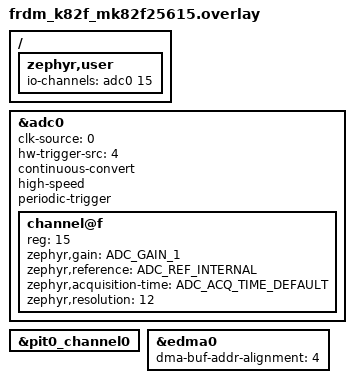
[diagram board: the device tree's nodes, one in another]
/*
 * SPDX-License-Identifier: Apache-2.0
 *
 * Copyright (c) 2023 Benjamin Björnsson <benjamin.bjornsson@gmail.com>
 */

/ {
	zephyr,user {
		io-channels = <&adc0 15>;
	};
};

&adc0 {
	#address-cells = <1>;
	#size-cells = <0>;
	clk-source = <0>;
	hw-trigger-src = <4>;
	continuous-convert;
	high-speed;
	periodic-trigger;
	status = "okay";

	channel@f {
		reg = <15>;
		zephyr,gain = "ADC_GAIN_1";
		zephyr,reference = "ADC_REF_INTERNAL";
		zephyr,acquisition-time = <ADC_ACQ_TIME_DEFAULT>;
		zephyr,resolution = <12>;
	};
};

test_counter: &pit0_channel0 {
	status = "okay";
};

&edma0 {
	dma-buf-addr-alignment = <4>;
};
